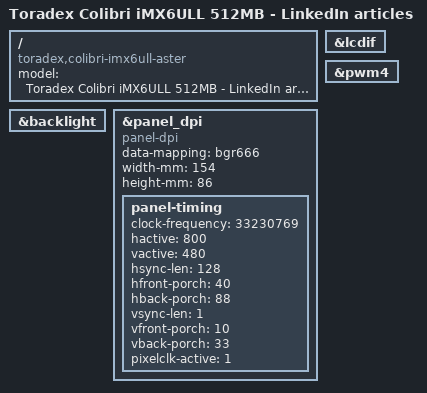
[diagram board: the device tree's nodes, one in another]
/*
 * Copyright 2023 Charles Dias
 *
 * SPDX-License-Identifier: MIT
 */

/dts-v1/;

#include "imx6ull-colibri-nonwifi.dtsi"
#include "imx6ull-colibri-aster.dtsi"

/ {
    model = "Toradex Colibri iMX6ULL 512MB - LinkedIn articles";
    compatible = "toradex,colibri-imx6ull-aster",
            "toradex,colibri-imx6ull",
            "fsl,imx6ull";
};

// Enable the parallel RGB interface on the Colibri iMX6ULL.

&backlight {
    status = "okay";
};

&lcdif {
    status = "okay";
};

&panel_dpi {
    data-mapping = "bgr666";
    status = "okay";
};

&pwm4 {
    status = "okay";
};

// Panel with a resolution of 800x480 pixel.
&panel_dpi {
    compatible = "panel-dpi";
    status = "okay";
 
    width-mm = <154>;
    height-mm = <86>;
 
    panel-timing {
        clock-frequency = <33230769>;
        hactive = <800>;
        vactive = <480>;
        hsync-len = <128>;
        hfront-porch = <40>;
        hback-porch = <88>;
        vsync-len = <1>;
        vfront-porch = <10>;
        vback-porch = <33>;
        pixelclk-active = <1>;
    };
};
